# ARMCM3 register map
Vendor: ARM Ltd.; Series: ARMCM; File version: 1.2
CPU: CM3 r1p1, little endian, no MPU, no FPU, 4 interrupt priority bits
Registers are 32-bit, read-write, reset 0x0 unless marked. A register's access mark holds for its fields unless they carry their own. Offsets are from the block's base; [hi:lo] are bit positions; {n}, {i} and the like mark numbered series.

## SCB — System Control Block
Base 0xE000ED00
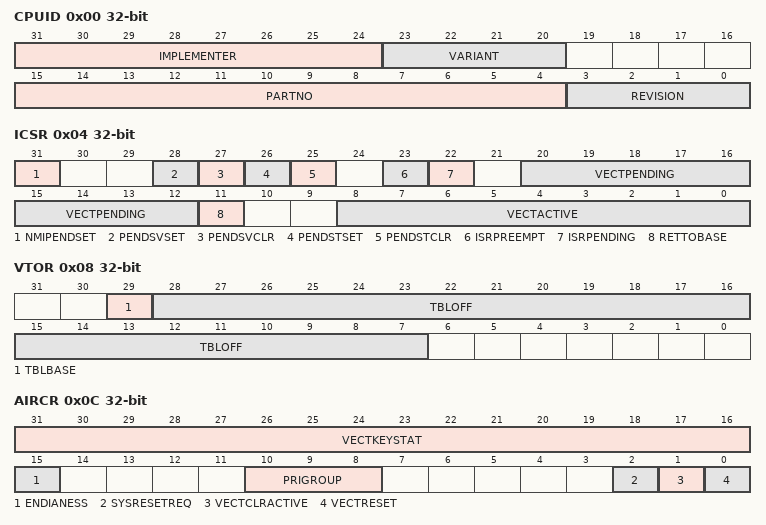
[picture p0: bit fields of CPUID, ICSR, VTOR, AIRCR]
0x00 CPUID read — CPUID Base Register
  [31:24] IMPLEMENTER, [23:20] VARIANT, [15:4] PARTNO, [3:0] REVISION
0x04 ICSR — Interrupt Control State Register
  [31] NMIPENDSET — Setting this bit will activate an NMI. Since NMI is higher priority than other exceptions, the NMI exception will activate as soon as it is registered.
  [28] PENDSVSET — Set a pending PendSV interrupt. This is normally used to request a context switch. Reads back with current state (1 if Pending, 0 if not).
  [27] PENDSVCLR — Clear a pending PendSV interrupt.
  [26] PENDSTSET — Set a pending SysTick. Reads back with current state (1 if Pending, 0 if not).
  [25] PENDSTCLR — Clear a pending SysTick (whether set here or by the timer hardware).
  [23] ISRPREEMPT — If set, a pending exception will be serviced on exit from the debug halt state.
  [22] ISRPENDING — Indicates if an external configurable (NVIC generated) interrupt is pending.
  [20:12] VECTPENDING — Indicates the exception number for the highest priority pending exception. value == 0: no pending exceptions
  [11] RETTOBASE — This bit is 1 when the set of all active exceptions minus the IPSR_current_exception yields the empty set.
  [8:0] VECTACTIVE — 0:thread mode. >1:the exception number for the current executing exception
0x08 VTOR — Vector Table Offset Register
  [29] TBLBASE — 0:Table base is in CODE, base address 0x00000000. 1:Table base is in RAM, base address 0x20000000
  [28:7] TBLOFF — Table offset address[28:7] from the base address defined by TBLBASE.
0x0C AIRCR — Application Interrupt/Reset Control Register
  [31:16] VECTKEYSTAT — Key and status
  [15] ENDIANESS — Big endian
  [10:8] PRIGROUP — Causes a signal to be asserted to the outer system that indicates a reset is requested.
  [2] SYSRESETREQ — Interrupt priority grouping
  [1] VECTCLRACTIVE — Clear active vector
  [0] VECTRESET — System Reset
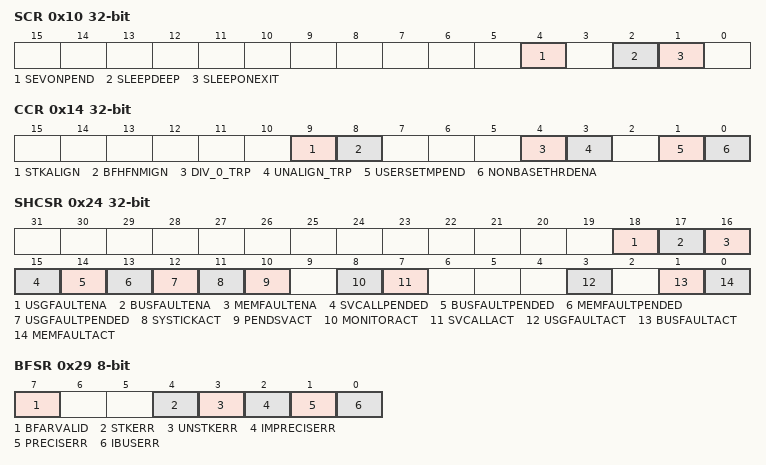
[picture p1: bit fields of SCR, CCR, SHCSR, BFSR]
0x10 SCR — System Control Register
  [4] SEVONPEND — WFE to wake up when an interrupt moves from inactive to pended.
  [2] SLEEPDEEP
  [1] SLEEPONEXIT — Sleep on exit when returning from Handler mode to Thread mode.
0x14 CCR — Configuration and Control Register
  [9] STKALIGN — 1: on exception entry, the SP used prior to the exception is adjusted to be 8-byte aligned and the context to restore it is saved.0: only 4-byte alignment is guaranteed for the SP used prior to the exception on exception entry.
  [8] BFHFNMIGN — When enabled (=1), this causes handlers running at priority -1 and -2 to ignore Precise data access faults. When disabled (=0), these bus faults will cause a lock-up as explained in Unrecoverable exception cases on page B1-43.
  [4] DIV_0_TRP — Enable bit (=1) for trap on Divide by 0.
  [3] UNALIGN_TRP — Enable bit (=1) for trapping unaligned half or full word accesses.
  [1] USERSETMPEND — When this bit is set (=1), the core allows unprivileged (user) code to write the Software Trigger Interrupt register. See Software Trigger Interrupt Register on page B3-23.
  [0] NONBASETHRDENA — 0 (default): Thread state can only be entered at the Base level of activation (will fault if attempted to another level of activation).
{0x14+4i} SHPR{i} (i=1..3) — System Handlers {4i}-{4i+3} Priority Register
0x24 SHCSR — System Handler Control and State Register
  [18] USGFAULTENA — Enable for UsageFault.
  [17] BUSFAULTENA — Enable for BusFault.
  [16] MEMFAULTENA — Enable for MemManage fault.
  [15] SVCALLPENDED — Reads as 1 if SVCall is Pending.
  [14] BUSFAULTPENDED — Reads as 1 if BusFault is Pending.
  [13] MEMFAULTPENDED — Reads as 1 if MemManage is Pending.
  [12] USGFAULTPENDED — Reads as 1 if UsageFault is Pending.
  [11] SYSTICKACT — Reads as 1 if SysTick is Active.
  [10] PENDSVACT — Reads as 1 if PendSV is Active.
  [8] MONITORACT — Reads as 1 if the Monitor is Active.
  [7] SVCALLACT — Reads as 1 if SVCall is Active.
  [3] USGFAULTACT — Reads as 1 if UsageFault is Active.
  [1] BUSFAULTACT — Reads as 1 if BusFault is Active.
  [0] MEMFAULTACT — Reads as 1 if MemManage is Active.
0x28 CFSR — Configurable Fault Status Registers
0x29 BFSR 8-bit — BusFault Status Register
  [7] BFARVALID — This bit is set if the BFAR register has valid contents.
  [4] STKERR — This bit indicates a derived bus fault has occurred on exception entry.
  [3] UNSTKERR — This bit indicates a derived bus fault has occurred on exception return.
  [2] IMPRECISERR — Imprecise data access error.
  [1] PRECISERR — Precise data access error. The BFAR is written with the faulting address.
  [0] IBUSERR — This bit indicates a bus fault on an instruction prefetch.
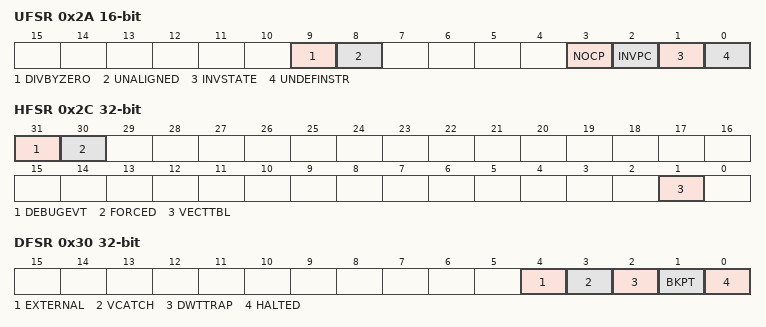
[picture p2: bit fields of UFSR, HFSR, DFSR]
0x2A UFSR 16-bit — UsageFault Status Register
  [9] DIVBYZERO — Divide by zero error. When SDIV or UDIV instruction is used with a divisor of 0, this fault will occur if DIV_0_TRP is enabled.
  [8] UNALIGNED — Unaligned access error. Multi-word accesses always fault if not word aligned. Unaligned word and halfwords can be configured to fault (UNALIGN_TRP is enabled)
  [3] NOCP — Coprocessor access error (the coprocessor is disabled or not present)
  [2] INVPC — Integrity check error on EXC_RETURN.
  [1] INVSTATE — Invalid EPSR.T bit or illegal EPSR.IT bits for executing instruction
  [0] UNDEFINSTR — Undefined instruction executed (including those associated with an enabled Coprocessor).
0x2C HFSR — Hard Fault Status Register
  [31] DEBUGEVT — Debug event, and the Debug Fault Status Register has been updated. Only set when halting debug is disabled (C_DEBUGEN = 0)
  [30] FORCED — Configurable fault cannot be activated due to priority or because it is disabled. Priority escalated to a HardFault exception.
  [1] VECTTBL — Fault was due to vector table read on exception processing.
0x30 DFSR — Debug Fault Status Register
  [4] EXTERNAL — An asynchronous exception generated due to the assertion of EDBGRQ.
  [3] VCATCH — Vector catch triggered. Corresponding FSR will contain the primary cause of the exception.
  [2] DWTTRAP — Data Watchpoint and Trace trap. Indicates that the core halted due to at least one DWT trap event.
  [1] BKPT — BKPT instruction executed or breakpoint match in FPB.
  [0] HALTED — Halt request, including step debug command. Stopped on next instruction.
0x34 MMAR — MemManage Address Register
0x38 BFAR — BusFault Address Register
0x3C AFSR — Auxiliary Fault Status Register
